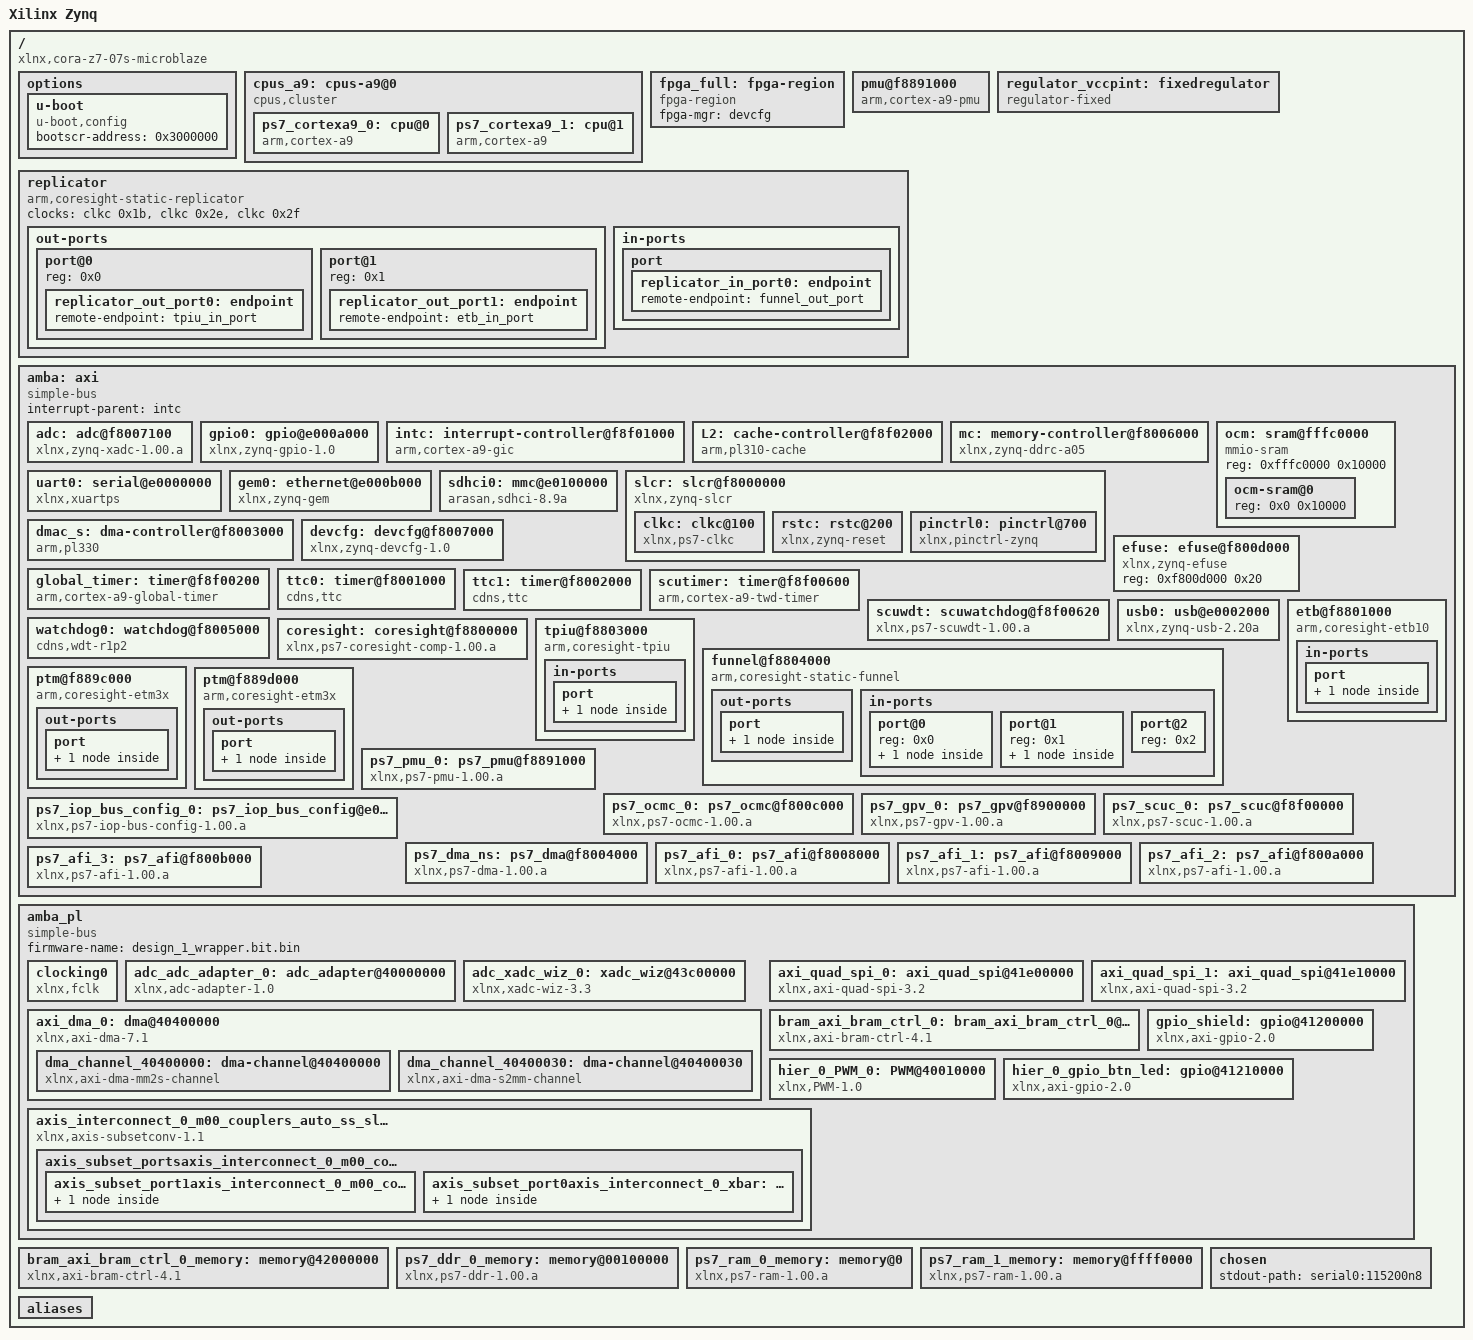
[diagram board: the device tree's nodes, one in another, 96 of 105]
/dts-v1/;
/ {
        #address-cells = <0x1>;
        #size-cells = <0x1>;
        compatible = "xlnx,cora-z7-07s-microblaze";
        model = "Xilinx Zynq";
        board = "cora-z7-07s";
        device_id = "7z007s";
        slrcount = <0x1>;
        family = "Zynq";
        speed_grade = "1";
        pruned-sdt = <0x1>;

        options {

                u-boot {
                        compatible = "u-boot,config";
                        bootscr-address = /bits/ 64 <0x3000000>;
                };
        };

        cpus_a9: cpus-a9@0 {
                phandle = <0x39>;
                #address-cells = <0x1>;
                #size-cells = <0x0>;
                compatible = "cpus,cluster";
                address-map = <0xf0000000 &amba 0xf0000000 0x10000000>,
                 <0x42000000 &bram_axi_bram_ctrl_0_memory 0x42000000 0x2000>,
                 <0x42000000 &bram_axi_bram_ctrl_0 0x42000000 0x2000>,
                 <0x100000 &ps7_ddr_0_memory 0x100000 0x1ff00000>,
                 <0x0 &ps7_ram_0_memory 0x0 0x30000>,
                 <0xffff0000 &ps7_ram_1_memory 0xffff0000 0xfe00>,
                 <0x40000000 &adc_adc_adapter_0 0x40000000 0x10000>,
                 <0x40010000 &hier_0_PWM_0 0x40010000 0x10000>,
                 <0x40400000 &axi_dma_0 0x40400000 0x10000>,
                 <0x41200000 &gpio_shield 0x41200000 0x10000>,
                 <0x41210000 &hier_0_gpio_btn_led 0x41210000 0x10000>,
                 <0x41e00000 &axi_quad_spi_0 0x41e00000 0x10000>,
                 <0x41e10000 &axi_quad_spi_1 0x41e10000 0x10000>,
                 <0x43c00000 &adc_xadc_wiz_0 0x43c00000 0x10000>,
                 <0xf8008000 &ps7_afi_0 0xf8008000 0x1000>,
                 <0xf8009000 &ps7_afi_1 0xf8009000 0x1000>,
                 <0xf800a000 &ps7_afi_2 0xf800a000 0x1000>,
                 <0xf800b000 &ps7_afi_3 0xf800b000 0x1000>,
                 <0xf8800000 &coresight 0xf8800000 0x100000>,
                 <0xf8006000 &mc 0xf8006000 0x1000>,
                 <0xf8007000 &devcfg 0xf8007000 0x100>,
                 <0xf8004000 &ps7_dma_ns 0xf8004000 0x1000>,
                 <0xf8003000 &dmac_s 0xf8003000 0x1000>,
                 <0xe000b000 &gem0 0xe000b000 0x1000>,
                 <0xf8f00200 &global_timer 0xf8f00200 0x100>,
                 <0xe000a000 &gpio0 0xe000a000 0x1000>,
                 <0xf8900000 &ps7_gpv_0 0xf8900000 0x100000>,
                 <0xf8f01000 &intc 0xf8f01000 0x1000>,
                 <0xe0200000 &ps7_iop_bus_config_0 0xe0200000 0x1000>,
                 <0xf8f02000 &L2 0xf8f02000 0x1000>,
                 <0xf800c000 &ps7_ocmc_0 0xf800c000 0x1000>,
                 <0xf8891000 &ps7_pmu_0 0xf8891000 0x1000>,
                 <0xf8f00000 &ps7_scuc_0 0xf8f00000 0xfd>,
                 <0xf8f00600 &scutimer 0xf8f00600 0x20>,
                 <0xf8f00620 &scuwdt 0xf8f00620 0xe0>,
                 <0xe0100000 &sdhci0 0xe0100000 0x1000>,
                 <0xf8000000 &slcr 0xf8000000 0x1000>,
                 <0xf8001000 &ttc0 0xf8001000 0x1000>,
                 <0xe0000000 &uart0 0xe0000000 0x1000>,
                 <0xe0002000 &usb0 0xe0002000 0x1000>,
                 <0xf8007100 &adc 0xf8007100 0x21>;
                #ranges-address-cells = <0x1>;
                #ranges-size-cells = <0x1>;

                ps7_cortexa9_0: cpu@0 {
                        phandle = <0x34>;
                        compatible = "arm,cortex-a9";
                        device_type = "cpu";
                        reg = <0x0>;
                        clocks = <&clkc 0x3>;
                        clock-latency = <0x3e8>;
                        cpu0-supply = <&regulator_vccpint>;
                        operating-points = <0xa2c2b 0xf4240 0x51616 0xf4240>;
                        xlnx,i-cache-size = <0x8000>;
                        xlnx,d-cache-line-size = <0x14>;
                        xlnx,i-cache-line-size = <0x14>;
                        xlnx,cpu-1x-clk-freq-hz = <0x6750918>;
                        xlnx,ip-name = "ps7_cortexa9";
                        xlnx,d-cache-size = <0x8000>;
                        xlnx,num-cores = <0x1>;
                        xlnx,cpu-clk-freq-hz = <0x26be3680>;
                        bus-handle = <0x1>;
                };

                ps7_cortexa9_1: cpu@1 {
                        phandle = <0x36>;
                        compatible = "arm,cortex-a9";
                        device_type = "cpu";
                        reg = <0x1>;
                        clocks = <&clkc 0x3>;
                };
        };

        fpga_full: fpga-region {
                phandle = <0x3a>;
                compatible = "fpga-region";
                fpga-mgr = <&devcfg>;
                #address-cells = <0x1>;
                #size-cells = <0x1>;
                ranges;
        };

        pmu@f8891000 {
                compatible = "arm,cortex-a9-pmu";
                interrupts = <0x0 0x5 0x4 0x0 0x6 0x4>;
                interrupt-parent = <&intc>;
                reg = <0xf8891000 0x1000 0xf8893000 0x1000>;
        };

        regulator_vccpint: fixedregulator {
                phandle = <0x2b>;
                compatible = "regulator-fixed";
                regulator-name = "VCCPINT";
                regulator-min-microvolt = <0xf4240>;
                regulator-max-microvolt = <0xf4240>;
                regulator-boot-on;
                regulator-always-on;
        };

        replicator {
                compatible = "arm,coresight-static-replicator";
                clocks = <&clkc 0x1b>,
                 <&clkc 0x2e>,
                 <&clkc 0x2f>;
                clock-names = "apb_pclk", "dbg_trc", "dbg_apb";

                out-ports {
                        #address-cells = <0x1>;
                        #size-cells = <0x0>;

                        port@0 {
                                reg = <0x0>;

                                replicator_out_port0: endpoint {
                                        phandle = <0x30>;
                                        remote-endpoint = <&tpiu_in_port>;
                                };
                        };

                        port@1 {
                                reg = <0x1>;

                                replicator_out_port1: endpoint {
                                        phandle = <0x2f>;
                                        remote-endpoint = <&etb_in_port>;
                                };
                        };
                };

                in-ports {

                        port {

                                replicator_in_port0: endpoint {
                                        phandle = <0x31>;
                                        remote-endpoint = <&funnel_out_port>;
                                };
                        };
                };
        };

        amba: axi {
                phandle = <0x1>;
                bootph-all;
                compatible = "simple-bus";
                #address-cells = <0x1>;
                #size-cells = <0x1>;
                interrupt-parent = <&intc>;
                ranges;

                adc: adc@f8007100 {
                        phandle = <0x29>;
                        compatible = "xlnx,zynq-xadc-1.00.a";
                        reg = <0xf8007100 0x20>;
                        interrupts = <0x0 0x7 0x4>;
                        interrupt-parent = <&intc>;
                        clocks = <&clkc 0xc>;
                        status = "okay";
                        xlnx,ip-name = "ps7_xadc";
                        xlnx,name = "ps7_xadc_0";
                };

                gpio0: gpio@e000a000 {
                        phandle = <0x1a>;
                        compatible = "xlnx,zynq-gpio-1.0";
                        #gpio-cells = <0x2>;
                        clocks = <&clkc 0x2a>;
                        gpio-controller;
                        interrupt-controller;
                        #interrupt-cells = <0x2>;
                        interrupt-parent = <&intc>;
                        interrupts = <0x0 0x14 0x4>;
                        reg = <0xe000a000 0x1000>;
                        xlnx,mio-gpio-mask = <0x5600>;
                        status = "okay";
                        gpio-mask-high = <0x0>;
                        xlnx,emio-gpio-width = <0x40>;
                        xlnx,ip-name = "ps7_gpio";
                        gpio-mask-low = <0x5600>;
                        emio-gpio-width = <0x40>;
                        xlnx,name = "ps7_gpio_0";
                };

                intc: interrupt-controller@f8f01000 {
                        phandle = <0x1c>;
                        compatible = "arm,cortex-a9-gic";
                        #interrupt-cells = <0x3>;
                        interrupt-controller;
                        reg = <0xf8f01000 0x1000 0xf8f00100 0x100>;
                        status = "okay";
                        xlnx,irq-f2p-mode = "DIRECT";
                        xlnx,ip-name = "ps7_intc_dist";
                        xlnx,name = "ps7_intc_dist_0";
                };

                L2: cache-controller@f8f02000 {
                        phandle = <0x1e>;
                        compatible = "arm,pl310-cache";
                        reg = <0xf8f02000 0x1000>;
                        interrupts = <0x0 0x2 0x4>;
                        arm,data-latency = <0x3 0x2 0x2>;
                        arm,tag-latency = <0x2 0x2 0x2>;
                        cache-unified;
                        cache-level = <0x2>;
                        status = "okay";
                        xlnx,ip-name = "ps7_pl310";
                        xlnx,name = "ps7_pl310_0";
                };

                mc: memory-controller@f8006000 {
                        phandle = <0x14>;
                        compatible = "xlnx,zynq-ddrc-a05";
                        reg = <0xf8006000 0x1000>;
                        status = "okay";
                        xlnx,ddr-clk-freq-hz = <0x1f4add40>;
                        xlnx,ip-name = "ps7_ddrc";
                        xlnx,has-ecc = <0x0>;
                        xlnx,name = "ps7_ddrc_0";
                };

                ocm: sram@fffc0000 {
                        phandle = <0x3f>;
                        compatible = "mmio-sram";
                        reg = <0xfffc0000 0x10000>;
                        #address-cells = <0x1>;
                        #size-cells = <0x1>;
                        ranges = <0x0 0xfffc0000 0x10000>;

                        ocm-sram@0 {
                                reg = <0x0 0x10000>;
                        };
                };

                uart0: serial@e0000000 {
                        phandle = <0x27>;
                        compatible = "xlnx,xuartps", "cdns,uart-r1p8";
                        status = "okay";
                        clocks = <&clkc 0x17>,
                         <&clkc 0x28>;
                        clock-names = "uart_clk", "pclk";
                        reg = <0xe0000000 0x1000>;
                        interrupts = <0x0 0x1b 0x4>;
                        interrupt-parent = <&intc>;
                        device_type = "serial";
                        xlnx,clock-freq = <0x5f5e100>;
                        xlnx,has-modem = <0x0>;
                        xlnx,ip-name = "ps7_uart";
                        cts-override;
                        port-number = <0x0>;
                        xlnx,uart-clk-freq-hz = <0x5f5e100>;
                        xlnx,name = "ps7_uart_0";
                };

                gem0: ethernet@e000b000 {
                        phandle = <0x18>;
                        compatible = "xlnx,zynq-gem", "cdns,gem";
                        reg = <0xe000b000 0x1000>;
                        status = "okay";
                        interrupts = <0x0 0x16 0x4>;
                        interrupt-parent = <&intc>;
                        clocks = <&clkc 0x1e>,
                         <&clkc 0x1e>,
                         <&clkc 0xd>;
                        clock-names = "pclk", "hclk", "tx_clk";
                        #address-cells = <0x1>;
                        #size-cells = <0x0>;
                        xlnx,has-mdio = <0x1>;
                        phy-mode = "rgmii-id";
                        xlnx,enet-slcr-1000mbps-div0 = <0x8>;
                        xlnx,enet-slcr-10mbps-div0 = <0x8>;
                        enet-reset = <0x1a 0x9 0x0>;
                        xlnx,enet-slcr-1000mbps-div1 = <0x1>;
                        xlnx,enet-slcr-10mbps-div1 = <0x32>;
                        xlnx,ip-name = "ps7_ethernet";
                        xlnx,eth-mode = <0x1>;
                        xlnx,enet-reset = "MIO , 9";
                        xlnx,enet-clk-freq-hz = <0x7735940>;
                        xlnx,enet-slcr-100mbps-div0 = <0x8>;
                        xlnx,ptp-enet-clock = <0x6750918>;
                        xlnx,enet-slcr-100mbps-div1 = <0x5>;
                        xlnx,name = "ps7_ethernet_0";
                };

                sdhci0: mmc@e0100000 {
                        phandle = <0x24>;
                        compatible = "arasan,sdhci-8.9a";
                        status = "okay";
                        clock-names = "clk_xin", "clk_ahb";
                        clocks = <&clkc 0x15>,
                         <&clkc 0x20>;
                        interrupt-parent = <&intc>;
                        interrupts = <0x0 0x18 0x4>;
                        reg = <0xe0100000 0x1000>;
                        xlnx,has-power = <0x0>;
                        xlnx,ip-name = "ps7_sdio";
                        xlnx,sdio-clk-freq-hz = <0x5f5e100>;
                        xlnx,has-wp = <0x0>;
                        xlnx,has-cd = <0x1>;
                        xlnx,name = "ps7_sd_0";
                };

                slcr: slcr@f8000000 {
                        phandle = <0x25>;
                        bootph-all;
                        #address-cells = <0x1>;
                        #size-cells = <0x1>;
                        compatible = "xlnx,zynq-slcr", "syscon", "simple-mfd";
                        reg = <0xf8000000 0x1000>;
                        ranges;
                        status = "okay";
                        xlnx,ip-name = "ps7_slcr";
                        xlnx,name = "ps7_slcr_0";

                        clkc: clkc@100 {
                                phandle = <0x2a>;
                                bootph-all;
                                #clock-cells = <0x1>;
                                compatible = "xlnx,ps7-clkc";
                                fclk-enable = <0x1>;
                                clock-output-names = "armpll", "ddrpll", "iopll", "cpu_6or4x", "cpu_3or2x", "cpu_2x", "cpu_1x", "ddr2x", "ddr3x", "dci", "lqspi", "smc", "pcap", "gem0", "gem1", "fclk0", "fclk1", "fclk2", "fclk3", "can0", "can1", "sdio0", "sdio1", "uart0", "uart1", "spi0", "spi1", "dma", "usb0_aper", "usb1_aper", "gem0_aper", "gem1_aper", "sdio0_aper", "sdio1_aper", "spi0_aper", "spi1_aper", "can0_aper", "can1_aper", "i2c0_aper", "i2c1_aper", "uart0_aper", "uart1_aper", "gpio_aper", "lqspi_aper", "smc_aper", "swdt", "dbg_trc", "dbg_apb";
                                reg = <0x100 0x100>;
                                ps-clk-frequency = <0x2faf080>;
                        };

                        rstc: rstc@200 {
                                phandle = <0x49>;
                                compatible = "xlnx,zynq-reset";
                                reg = <0x200 0x48>;
                                #reset-cells = <0x1>;
                                syscon = <&slcr>;
                        };

                        pinctrl0: pinctrl@700 {
                                phandle = <0x4a>;
                                compatible = "xlnx,pinctrl-zynq";
                                reg = <0x700 0x200>;
                                syscon = <&slcr>;
                        };
                };

                dmac_s: dma-controller@f8003000 {
                        phandle = <0x17>;
                        compatible = "arm,pl330", "arm,primecell";
                        reg = <0xf8003000 0x1000>;
                        interrupt-parent = <&intc>;
                        interrupts = <0x0 0xd 0x4 0x0 0xe 0x4 0x0 0xf 0x4 0x0 0x10 0x4 0x0 0x11 0x4 0x0 0x28 0x4 0x0 0x29 0x4 0x0 0x2a 0x4 0x0 0x2b 0x4>;
                        #dma-cells = <0x1>;
                        clocks = <&clkc 0x1b>;
                        clock-names = "apb_pclk";
                        status = "okay";
                        xlnx,ip-name = "ps7_dma";
                        xlnx,is-secure;
                        xlnx,name = "ps7_dma_s";
                };

                devcfg: devcfg@f8007000 {
                        phandle = <0x15>;
                        compatible = "xlnx,zynq-devcfg-1.0";
                        reg = <0xf8007000 0x100>;
                        interrupt-parent = <&intc>;
                        interrupts = <0x0 0x8 0x4>;
                        clocks = <&clkc 0xc>,
                         <&clkc 0xf>,
                         <&clkc 0x10>,
                         <&clkc 0x11>,
                         <&clkc 0x12>;
                        clock-names = "ref_clk", "fclk0", "fclk1", "fclk2", "fclk3";
                        syscon = <&slcr>;
                        status = "okay";
                        xlnx,ip-name = "ps7_dev_cfg";
                        xlnx,name = "ps7_dev_cfg_0";
                };

                efuse: efuse@f800d000 {
                        phandle = <0x4b>;
                        compatible = "xlnx,zynq-efuse";
                        reg = <0xf800d000 0x20>;
                };

                global_timer: timer@f8f00200 {
                        phandle = <0x19>;
                        compatible = "arm,cortex-a9-global-timer";
                        reg = <0xf8f00200 0x20>;
                        interrupts = <0x1 0xb 0x301>;
                        interrupt-parent = <&intc>;
                        clocks = <&clkc 0x4>;
                        status = "okay";
                        xlnx,ip-name = "ps7_globaltimer";
                        xlnx,name = "ps7_globaltimer_0";
                };

                ttc0: timer@f8001000 {
                        phandle = <0x26>;
                        interrupt-parent = <&intc>;
                        interrupts = <0x0 0xa 0x4 0x0 0xb 0x4 0x0 0xc 0x4>;
                        compatible = "cdns,ttc";
                        clocks = <&clkc 0x6>;
                        reg = <0xf8001000 0x1000>;
                        xlnx,ttc-clk2-freq-hz = <0x6750918>;
                        xlnx,ttc-clk1-clksrc = <0x0>;
                        status = "okay";
                        xlnx,clock-freq = <0x6750918>;
                        xlnx,ttc-clk2-clksrc = <0x0>;
                        xlnx,ip-name = "ps7_ttc";
                        xlnx,ttc-clk0-freq-hz = <0x6750918>;
                        xlnx,ttc-clk1-freq-hz = <0x6750918>;
                        xlnx,ttc-clk0-clksrc = <0x0>;
                        xlnx,name = "ps7_ttc_0";
                };

                ttc1: timer@f8002000 {
                        phandle = <0x4c>;
                        interrupt-parent = <&intc>;
                        interrupts = <0x0 0x25 0x4 0x0 0x26 0x4 0x0 0x27 0x4>;
                        compatible = "cdns,ttc";
                        clocks = <&clkc 0x6>;
                        reg = <0xf8002000 0x1000>;
                };

                scutimer: timer@f8f00600 {
                        phandle = <0x22>;
                        bootph-all;
                        interrupt-parent = <&intc>;
                        interrupts = <0x1 0xd 0x301>;
                        compatible = "arm,cortex-a9-twd-timer";
                        reg = <0xf8f00600 0x20>;
                        clocks = <&clkc 0x4>;
                        status = "okay";
                        xlnx,ip-name = "ps7_scutimer";
                        xlnx,name = "ps7_scutimer_0";
                };

                scuwdt: scuwatchdog@f8f00620 {
                        phandle = <0x23>;
                        interrupt-parent = <&intc>;
                        interrupts = <0x1 0xe 0x4>;
                        compatible = "xlnx,ps7-scuwdt-1.00.a";
                        reg = <0xf8f00620 0xe0>;
                        status = "okay";
                        xlnx,ip-name = "ps7_scuwdt";
                        xlnx,name = "ps7_scuwdt_0";
                };

                usb0: usb@e0002000 {
                        phandle = <0x28>;
                        compatible = "xlnx,zynq-usb-2.20a", "chipidea,usb2";
                        status = "okay";
                        clocks = <&clkc 0x1c>;
                        interrupt-parent = <&intc>;
                        interrupts = <0x0 0x15 0x4>;
                        reg = <0xe0002000 0x1000>;
                        phy_type = "ulpi";
                        xlnx,usb-reset = "MIO , 46";
                        xlnx,ip-name = "ps7_usb";
                        xlnx,enable-superspeed = <0x0>;
                        usb-reset = <0x1a 0x2e 0x0>;
                        xlnx,name = "ps7_usb_0";
                };

                watchdog0: watchdog@f8005000 {
                        phandle = <0x4e>;
                        clocks = <&clkc 0x2d>;
                        compatible = "cdns,wdt-r1p2";
                        interrupt-parent = <&intc>;
                        interrupts = <0x0 0x9 0x1>;
                        reg = <0xf8005000 0x1000>;
                        timeout-sec = <0xa>;
                };

                coresight: coresight@f8800000 {
                        phandle = <0x13>;
                        compatible = "xlnx,ps7-coresight-comp-1.00.a";
                        status = "okay";
                        reg = <0xf8800000 0x100000>;
                        xlnx,ip-name = "ps7_coresight_comp";
                        xlnx,name = "ps7_coresight_comp_0";
                };

                etb@f8801000 {
                        compatible = "arm,coresight-etb10", "arm,primecell";
                        reg = <0xf8801000 0x1000>;
                        clocks = <&clkc 0x1b>,
                         <&clkc 0x2e>,
                         <&clkc 0x2f>;
                        clock-names = "apb_pclk", "dbg_trc", "dbg_apb";

                        in-ports {

                                port {

                                        etb_in_port: endpoint {
                                                phandle = <0x2d>;
                                                remote-endpoint = <&replicator_out_port1>;
                                        };
                                };
                        };
                };

                tpiu@f8803000 {
                        compatible = "arm,coresight-tpiu", "arm,primecell";
                        reg = <0xf8803000 0x1000>;
                        clocks = <&clkc 0x1b>,
                         <&clkc 0x2e>,
                         <&clkc 0x2f>;
                        clock-names = "apb_pclk", "dbg_trc", "dbg_apb";

                        in-ports {

                                port {

                                        tpiu_in_port: endpoint {
                                                phandle = <0x2c>;
                                                remote-endpoint = <&replicator_out_port0>;
                                        };
                                };
                        };
                };

                funnel@f8804000 {
                        compatible = "arm,coresight-static-funnel", "arm,primecell";
                        reg = <0xf8804000 0x1000>;
                        clocks = <&clkc 0x1b>,
                         <&clkc 0x2e>,
                         <&clkc 0x2f>;
                        clock-names = "apb_pclk", "dbg_trc", "dbg_apb";

                        out-ports {

                                port {

                                        funnel_out_port: endpoint {
                                                phandle = <0x2e>;
                                                remote-endpoint = <&replicator_in_port0>;
                                        };
                                };
                        };

                        in-ports {
                                #address-cells = <0x1>;
                                #size-cells = <0x0>;

                                port@0 {
                                        reg = <0x0>;

                                        funnel0_in_port0: endpoint {
                                                phandle = <0x35>;
                                                remote-endpoint = <&ptm0_out_port>;
                                        };
                                };

                                port@1 {
                                        reg = <0x1>;

                                        funnel0_in_port1: endpoint {
                                                phandle = <0x37>;
                                                remote-endpoint = <&ptm1_out_port>;
                                        };
                                };

                                port@2 {
                                        reg = <0x2>;
                                };
                        };
                };

                ptm@f889c000 {
                        compatible = "arm,coresight-etm3x", "arm,primecell";
                        reg = <0xf889c000 0x1000>;
                        clocks = <&clkc 0x1b>,
                         <&clkc 0x2e>,
                         <&clkc 0x2f>;
                        clock-names = "apb_pclk", "dbg_trc", "dbg_apb";
                        cpu = <&ps7_cortexa9_0>;

                        out-ports {

                                port {

                                        ptm0_out_port: endpoint {
                                                phandle = <0x32>;
                                                remote-endpoint = <&funnel0_in_port0>;
                                        };
                                };
                        };
                };

                ptm@f889d000 {
                        compatible = "arm,coresight-etm3x", "arm,primecell";
                        reg = <0xf889d000 0x1000>;
                        clocks = <&clkc 0x1b>,
                         <&clkc 0x2e>,
                         <&clkc 0x2f>;
                        clock-names = "apb_pclk", "dbg_trc", "dbg_apb";
                        cpu = <&ps7_cortexa9_1>;

                        out-ports {

                                port {

                                        ptm1_out_port: endpoint {
                                                phandle = <0x33>;
                                                remote-endpoint = <&funnel0_in_port1>;
                                        };
                                };
                        };
                };

                ps7_pmu_0: ps7_pmu@f8891000 {
                        phandle = <0x20>;
                        compatible = "xlnx,ps7-pmu-1.00.a";
                        status = "okay";
                        xlnx,ip-name = "ps7_pmu";
                        reg = <0xf8891000 0x1000 0xf8893000 0x1000>;
                        xlnx,name = "ps7_pmu_0";
                };

                ps7_ocmc_0: ps7_ocmc@f800c000 {
                        phandle = <0x1f>;
                        compatible = "xlnx,ps7-ocmc-1.00.a";
                        status = "okay";
                        xlnx,ip-name = "ps7_ocmc";
                        reg = <0xf800c000 0x1000>;
                        xlnx,name = "ps7_ocmc_0";
                };

                ps7_gpv_0: ps7_gpv@f8900000 {
                        phandle = <0x1b>;
                        compatible = "xlnx,ps7-gpv-1.00.a";
                        status = "okay";
                        xlnx,ip-name = "ps7_gpv";
                        reg = <0xf8900000 0x100000>;
                        xlnx,name = "ps7_gpv_0";
                };

                ps7_scuc_0: ps7_scuc@f8f00000 {
                        phandle = <0x21>;
                        compatible = "xlnx,ps7-scuc-1.00.a";
                        status = "okay";
                        xlnx,ip-name = "ps7_scuc";
                        reg = <0xf8f00000 0xfd>;
                        xlnx,name = "ps7_scuc_0";
                };

                ps7_iop_bus_config_0: ps7_iop_bus_config@e0200000 {
                        phandle = <0x1d>;
                        compatible = "xlnx,ps7-iop-bus-config-1.00.a";
                        status = "okay";
                        xlnx,ip-name = "ps7_iop_bus_config";
                        reg = <0xe0200000 0x1000>;
                        xlnx,name = "ps7_iop_bus_config_0";
                };

                ps7_dma_ns: ps7_dma@f8004000 {
                        phandle = <0x16>;
                        compatible = "xlnx,ps7-dma-1.00.a";
                        status = "okay";
                        xlnx,ip-name = "ps7_dma";
                        xlnx,is-secure;
                        reg = <0xf8004000 0x1000>;
                        xlnx,name = "ps7_dma_ns";
                };

                ps7_afi_0: ps7_afi@f8008000 {
                        phandle = <0xf>;
                        compatible = "xlnx,ps7-afi-1.00.a";
                        status = "okay";
                        xlnx,ip-name = "ps7_afi";
                        reg = <0xf8008000 0x1000>;
                        xlnx,name = "ps7_afi_0";
                };

                ps7_afi_1: ps7_afi@f8009000 {
                        phandle = <0x10>;
                        compatible = "xlnx,ps7-afi-1.00.a";
                        status = "okay";
                        xlnx,ip-name = "ps7_afi";
                        reg = <0xf8009000 0x1000>;
                        xlnx,name = "ps7_afi_1";
                };

                ps7_afi_2: ps7_afi@f800a000 {
                        phandle = <0x11>;
                        compatible = "xlnx,ps7-afi-1.00.a";
                        status = "okay";
                        xlnx,ip-name = "ps7_afi";
                        reg = <0xf800a000 0x1000>;
                        xlnx,name = "ps7_afi_2";
                };

                ps7_afi_3: ps7_afi@f800b000 {
                        phandle = <0x12>;
                        compatible = "xlnx,ps7-afi-1.00.a";
                        status = "okay";
                        xlnx,ip-name = "ps7_afi";
                        reg = <0xf800b000 0x1000>;
                        xlnx,name = "ps7_afi_3";
                };
        };

        amba_pl: amba_pl {
                phandle = <0x54>;
                ranges;
                compatible = "simple-bus";
                #address-cells = <0x1>;
                #size-cells = <0x1>;
                firmware-name = "design_1_wrapper.bit.bin";

                clocking0: clocking0 {
                        phandle = <0x55>;
                        compatible = "xlnx,fclk";
                        assigned-clocks = <&clkc 0xf>;
                        assigned-clock-rates = <0x2faf080>;
                        #clock-cells = <0x0>;
                        clock-output-names = "fabric_clk";
                        clocks = <&clkc 0xf>;
                };

                adc_adc_adapter_0: adc_adapter@40000000 {
                        phandle = <0x7>;
                        interrupts = <0x0 0x20 0x4>;
                        compatible = "xlnx,adc-adapter-1.0";
                        xlnx,ii = "undef";
                        xlnx,machine = <0x40>;
                        xlnx,s-axi-control-addr-width = <0x5>;
                        interrupt-parent = <&intc>;
                        xlnx,ip-name = "adc_adapter";
                        reg = <0x40000000 0x10000>;
                        clocks = <&clkc 0xf>;
                        xlnx,clk-period = <0xa>;
                        xlnx,s-axi-control-data-width = <0x20>;
                        xlnx,edk-iptype = "PERIPHERAL";
                        status = "okay";
                        clock-names = "ap_clk";
                        interrupt-names = "interrupt";
                        xlnx,combinational = <0x0>;
                        xlnx,latency = "undef";
                        xlnx,name = "adc_adc_adapter_0";
                };

                adc_xadc_wiz_0: xadc_wiz@43c00000 {
                        phandle = <0xe>;
                        xlnx,vccpint-alarm-upper = <0x1>;
                        xlnx,vccint-alarm-upper = <0xfb770>;
                        xlnx,timing-mode = "Continuous";
                        xlnx,enable-dclk;
                        xlnx,has-vccpint-alarm = <0x0>;
                        xlnx,alarm-limit-r2 = <0xa147>;
                        xlnx,has-jtagbusy = <0x0>;
                        xlnx,vbram-alarm-upper = <0x100590>;
                        xlnx,enable-jtagmodified;
                        xlnx,has-vbram-alarm = <0x0>;
                        xlnx,alarm-limit-r3 = <0xca33>;
                        xlnx,has-axi = <0x1>;
                        xlnx,vaux0 = <0x0>;
                        xlnx,alarm-limit-r4 = <0xa93a>;
                        xlnx,has-busy = <0x1>;
                        xlnx,enable-channel;
                        xlnx,vaux1 = <0x0>;
                        xlnx,has-vccaux-alarm = <0x0>;
                        xlnx,alarm-limit-r5 = <0x52c6>;
                        xlnx,dclk-frequency = <0x32>;
                        xlnx,vaux2 = <0x0>;
                        xlnx,alarm-limit-r6 = <0x9555>;
                        xlnx,vaux3 = <0x0>;
                        xlnx,ip-name = "xadc_wiz";
                        xlnx,alarm-limit-r7 = <0xae4e>;
                        xlnx,configuration-r0 = <0x3>;
                        xlnx,has-drp = <0x0>;
                        xlnx,vaux4 = <0x0>;
                        xlnx,sim-file-rel-path = "./";
                        reg = <0x43c00000 0x10000>;
                        xlnx,alarm-limit-r8 = <0x5999>;
                        xlnx,configuration-r1 = <0x31af>;
                        xlnx,external-mux-channel = "VP_VN";
                        xlnx,temperature-alarm-trigger = <0x55>;
                        xlnx,vaux5 = <0x0>;
                        xlnx,alarm-limit-r9 = <0x5111>;
                        xlnx,configuration-r2 = <0x200>;
                        xlnx,has-jtaglocked = <0x0>;
                        xlnx,vaux6 = <0x0>;
                        xlnx,vaux7 = <0x0>;
                        xlnx,vaux8 = <0x0>;
                        xlnx,vaux9 = <0x0>;
                        xlnx,vaux10 = <0x0>;
                        xlnx,has-vn = <0x1>;
                        xlnx,has-vccpaux-alarm = <0x0>;
                        xlnx,acquisition-time = <0x4>;
                        xlnx,vaux11 = <0x0>;
                        xlnx,has-temp-bus = <0x0>;
                        xlnx,xadc-starup-selection = "single_channel";
                        xlnx,enable-busy;
                        xlnx,data-width = <0x20>;
                        xlnx,vaux12 = <0x0>;
                        xlnx,sim-file-sel = "Default";
                        xlnx,has-vp = <0x1>;
                        xlnx,ip-type = <0x0>;
                        xlnx,temperature-alarm-ot-reset = <0x46>;
                        xlnx,vaux13 = <0x0>;
                        xlnx,enable-convst;
                        xlnx,vaux14 = <0x0>;
                        xlnx,vccpaux-alarm-lower = <0x1a17b0>;
                        xlnx,vccaux-alarm-lower = <0x1ab3f0>;
                        xlnx,vaux15 = <0x0>;
                        compatible = "xlnx,xadc-wiz-3.3", "xlnx,axi-xadc-1.00.a";
                        xlnx,has-external-mux = <0x0>;
                        xlnx,sampling-rate = <0xdf 0xe0288f62>;
                        xlnx,has-reset = <0x0>;
                        xlnx,adc-conversion-rate = <0x3c2>;
                        xlnx,vccddro-alarm-lower = <0x124f80>;
                        xlnx,enable-calibration-averaging;
                        xlnx,has-user-temp-alarm = <0x0>;
                        xlnx,enable-axi4stream;
                        xlnx,has-ot-alarm = <0x0>;
                        xlnx,has-convst = <0x0>;
                        xlnx,single-channel-selection = "VP_VN";
                        xlnx,startup-channel-selection = "single_channel";
                        xlnx,interface-selection = "Enable_AXI";
                        xlnx,vccpaux-alarm-upper = <0x1b7740>;
                        xlnx,vccaux-alarm-upper = <0x1cd6d0>;
                        status = "okay";
                        xlnx,sensor-offset-and-gain-calibration;
                        xlnx,vccddro-alarm-upper = <0x1312d0>;
                        xlnx,name = "adc_xadc_wiz_0";
                        xlnx,external-mux = "none";
                        xlnx,enable-eoc;
                        xlnx,enable-jtaglocked;
                        xlnx,sim-file-name = "design";
                        xlnx,temperature-alarm-reset = <0x3c>;
                        xlnx,addr-width = <0x20>;
                        clocks = <&clkc 0xf>,
                         <&clkc 0xf>;
                        xlnx,alarm-limit-r10 = <0x5555>;
                        xlnx,alarm-limit-r11 = <0x5111>;
                        xlnx,alarm-limit-r12 = <0x9999>;
                        xlnx,edk-iptype = "PERIPHERAL";
                        xlnx,alarm-limit-r13 = <0x91eb>;
                        xlnx,sequencer-mode;
                        xlnx,enable-jtagbusy;
                        xlnx,alarm-limit-r14 = <0x6aaa>;
                        xlnx,include-intr = <0x1>;
                        xlnx,alarm-limit-r15 = <0x6666>;
                        xlnx,fifo-depth = <0x7>;
                        clock-names = "s_axi_aclk", "s_axis_aclk";
                        xlnx,has-eoc = <0x1>;
                        xlnx,temperature-alarm-ot-trigger = <0x7d>;
                        xlnx,has-channel = <0x1>;
                        xlnx,enable-eos;
                        xlnx,vccpint-alarm-lower = <0xe7ef0>;
                        xlnx,vccint-alarm-lower = <0xecd10>;
                        xlnx,has-dclk = <0x1>;
                        xlnx,vbram-alarm-lower = <0xe7ef0>;
                        xlnx,num-wave = <0x1>;
                        xlnx,sequence-r0 = <0x100>;
                        xlnx,has-jtagmodified = <0x0>;
                        xlnx,sequence-r1 = <0x0>;
                        xlnx,enable-drp;
                        xlnx,sequence-r2 = <0x0>;
                        xlnx,has-vccint-alarm = <0x0>;
                        xlnx,channel-averaging = "None";
                        xlnx,sequence-r3 = <0x0>;
                        xlnx,has-axi4stream = <0x1>;
                        xlnx,sequence-r4 = <0x0>;
                        xlnx,sequence-r5 = <0x0>;
                        xlnx,adc-offset-and-gain-calibration;
                        xlnx,waveform-type = "CONSTANT";
                        xlnx,sequence-r6 = <0x0>;
                        xlnx,vccddro-volt = "1_2";
                        xlnx,sequence-r7 = <0x0>;
                        xlnx,has-vccddro-alarm = <0x0>;
                        xlnx,alarm-limit-r0 = <0xb5ed>;
                        xlnx,has-convstclk = <0x0>;
                        xlnx,has-eos = <0x1>;
                        xlnx,stimulus-freq = <0x1>;
                        xlnx,single-channel-enable-calibration;
                        xlnx,alarm-limit-r1 = <0x57e4>;
                        xlnx,component-name = "design_1_xadc_wiz_0_0";
                        xlnx,external-muxaddr-enable = <0x0>;
                };

                axi_dma_0: dma@40400000 {
                        phandle = <0x9>;
                        interrupts = <0x0 0x1e 0x4 0x0 0x1f 0x4>;
                        compatible = "xlnx,axi-dma-7.1", "xlnx,axi-dma-1.00.a";
                        xlnx,s2mm-data-width = <0x20>;
                        xlnx,mm2s-burst-size = <0x10>;
                        xlnx,m-axi-mm2s-data-width = <0x20>;
                        xlnx,num-s2mm-channels = <0x1>;
                        xlnx,dlytmr-resolution = <0x7d>;
                        interrupt-parent = <&intc>;
                        xlnx,sg-length-width = <0xe>;
                        xlnx,prmry-is-aclk-async = <0x0>;
                        xlnx,include-s2mm-sf = <0x1>;
                        #dma-cells = <0x1>;
                        xlnx,ip-name = "axi_dma";
                        xlnx,single-interface = <0x0>;
                        xlnx,sg-include-stscntrl-strm = <0x0>;
                        xlnx,include-s2mm-dre = <0x0>;
                        reg = <0x40400000 0x10000>;
                        xlnx,addr-width = <0x20>;
                        xlnx,include-s2mm = <0x1>;
                        clocks = <&clkc 0xf>,
                         <&clkc 0xf>,
                         <&clkc 0xf>;
                        xlnx,s-axis-s2mm-tdata-width = <0x20>;
                        xlnx,micro-dma = <0x0>;
                        xlnx,increase-throughput = <0x0>;
                        xlnx,mm2s-data-width = <0x20>;
                        xlnx,addrwidth = <0x20>;
                        xlnx,sg-use-stsapp-length = <0x0>;
                        xlnx,m-axis-mm2s-tdata-width = <0x20>;
                        xlnx,edk-iptype = "PERIPHERAL";
                        xlnx,s2mm-burst-size = <0x10>;
                        xlnx,m-axi-s2mm-data-width = <0x20>;
                        xlnx,num-mm2s-channels = <0x1>;
                        xlnx,enable-multi-channel = <0x0>;
                        status = "okay";
                        xlnx,include-mm2s-sf = <0x1>;
                        clock-names = "m_axi_mm2s_aclk", "m_axi_s2mm_aclk", "s_axi_lite_aclk";
                        interrupt-names = "mm2s_introut", "s2mm_introut";
                        xlnx,include-mm2s = <0x1>;
                        xlnx,include-mm2s-dre = <0x0>;
                        xlnx,name = "axi_dma_0";

                        dma_channel_40400000: dma-channel@40400000 {
                                phandle = <0x56>;
                                interrupts = <0x0 0x1e 0x4>;
                                xlnx,datawidth = <0x20>;
                                xlnx,device-id = <0x0>;
                                compatible = "xlnx,axi-dma-mm2s-channel";
                                dma-channels = <0x1>;
                        };

                        dma_channel_40400030: dma-channel@40400030 {
                                phandle = <0x57>;
                                interrupts = <0x0 0x1f 0x4>;
                                xlnx,datawidth = <0x20>;
                                xlnx,device-id = <0x0>;
                                compatible = "xlnx,axi-dma-s2mm-channel";
                                dma-channels = <0x1>;
                        };
                };

                axi_quad_spi_0: axi_quad_spi@41e00000 {
                        phandle = <0xc>;
                        xlnx,select-xpm = <0x0>;
                        compatible = "xlnx,axi-quad-spi-3.2", "xlnx,xps-spi-2.00.a";
                        xlnx,lsb-stup = <0x0>;
                        xlnx,num-ss-bits = <0x1>;
                        xlnx,hasfifos = <0x1>;
                        xlnx,xip-mode = <0x0>;
                        xlnx,use-startup-ext = <0x0>;
                        xlnx,s-axi4-addr-width = <0x18>;
                        xlnx,byte-level-interrupt-en = <0x0>;
                        num-cs = <0x1>;
                        xlnx,xip-perf-mode = <0x1>;
                        xlnx,sck-ratio = <0x10>;
                        xlnx,s-axi4-id-width = <0x4>;
                        fifo-size = <0x10>;
                        xlnx,multiples16 = <0x1>;
                        xlnx,master-mode = <0x1>;
                        xlnx,shared-startup = <0x0>;
                        xlnx,ip-name = "axi_quad_spi";
                        xlnx,qspi-board-interface = "Custom";
                        reg = <0x41e00000 0x10000>;
                        xlnx,dual-quad-mode = <0x0>;
                        xlnx,new-seq-en = <0x1>;
                        bits-per-word = <0x8>;
                        clocks = <&clkc 0xf>,
                         <&clkc 0xf>;
                        xlnx,num-transfer-bits = <0x8>;
                        xlnx,spi-memory = <0x1>;
                        xlnx,s-axi4-data-width = <0x20>;
                        xlnx,edk-iptype = "PERIPHERAL";
                        xlnx,slaveonly = <0x0>;
                        xlnx,use-startup-int = <0x0>;
                        xlnx,use-startup = <0x0>;
                        xlnx,type-of-axi4-interface = <0x0>;
                        xlnx,async-clk = <0x0>;
                        xlnx,spi-mode = <0x0>;
                        xlnx,sck-ratio1 = <0x1>;
                        status = "okay";
                        xlnx,fifo-depth = <0x10>;
                        clock-names = "ext_spi_clk", "s_axi_aclk";
                        xlnx,use-board-flow;
                        xlnx,uc-family = <0x0>;
                        xlnx,spi-mem-addr-bits = <0x18>;
                        xlnx,axi-interface = <0x0>;
                        xlnx,Axi4-address = <0x0>;
                        xlnx,fifo-included = <0x1>;
                        xlnx,sub-family = "zynq";
                        xlnx,name = "axi_quad_spi_0";
                };

                axi_quad_spi_1: axi_quad_spi@41e10000 {
                        phandle = <0xd>;
                        xlnx,select-xpm = <0x0>;
                        compatible = "xlnx,axi-quad-spi-3.2", "xlnx,xps-spi-2.00.a";
                        xlnx,lsb-stup = <0x0>;
                        xlnx,num-ss-bits = <0x1>;
                        xlnx,hasfifos = <0x1>;
                        xlnx,xip-mode = <0x0>;
                        xlnx,use-startup-ext = <0x0>;
                        xlnx,s-axi4-addr-width = <0x18>;
                        xlnx,byte-level-interrupt-en = <0x0>;
                        num-cs = <0x1>;
                        xlnx,xip-perf-mode = <0x1>;
                        xlnx,sck-ratio = <0x10>;
                        xlnx,s-axi4-id-width = <0x4>;
                        fifo-size = <0x10>;
                        xlnx,multiples16 = <0x1>;
                        xlnx,master-mode = <0x1>;
                        xlnx,shared-startup = <0x0>;
                        xlnx,ip-name = "axi_quad_spi";
                        xlnx,qspi-board-interface = "Custom";
                        reg = <0x41e10000 0x10000>;
                        xlnx,dual-quad-mode = <0x0>;
                        xlnx,new-seq-en = <0x1>;
                        bits-per-word = <0x8>;
                        clocks = <&clkc 0xf>,
                         <&clkc 0xf>;
                        xlnx,num-transfer-bits = <0x8>;
                        xlnx,spi-memory = <0x1>;
                        xlnx,s-axi4-data-width = <0x20>;
                        xlnx,edk-iptype = "PERIPHERAL";
                        xlnx,slaveonly = <0x0>;
                        xlnx,use-startup-int = <0x0>;
                        xlnx,use-startup = <0x0>;
                        xlnx,type-of-axi4-interface = <0x0>;
                        xlnx,async-clk = <0x0>;
                        xlnx,spi-mode = <0x0>;
                        xlnx,sck-ratio1 = <0x1>;
                        status = "okay";
                        xlnx,fifo-depth = <0x10>;
                        clock-names = "ext_spi_clk", "s_axi_aclk";
                        xlnx,use-board-flow;
                        xlnx,uc-family = <0x0>;
                        xlnx,spi-mem-addr-bits = <0x18>;
                        xlnx,axi-interface = <0x0>;
                        xlnx,Axi4-address = <0x0>;
                        xlnx,fifo-included = <0x1>;
                        xlnx,sub-family = "zynq";
                        xlnx,name = "axi_quad_spi_1";
                };

                bram_axi_bram_ctrl_0: bram_axi_bram_ctrl_0@42000000 {
                        phandle = <0x3>;
                        xlnx,protocol = "AXI4";
                        xlnx,edk-special = "BRAM_CTRL";
                        compatible = "xlnx,axi-bram-ctrl-4.1", "xlnx,axi-bram-ctrl";
                        xlnx,ecc-onoff-reset-value = <0x0>;
                        xlnx,ecc-type = <0x0>;
                        xlnx,rd-cmd-optimization = <0x0>;
                        xlnx,memory-depth = <0x800>;
                        xlnx,use-ecc = <0x0>;
                        xlnx,fault-inject = <0x0>;
                        xlnx,ip-name = "axi_bram_ctrl";
                        reg = <0x42000000 0x2000>;
                        xlnx,bmg-instance = "EXTERNAL";
                        clocks = <&clkc 0xf>;
                        xlnx,s-axi-ctrl-addr-width = <0x20>;
                        xlnx,read-latency = <0x1>;
                        xlnx,id-width = <0x0>;
                        xlnx,s-axi-supports-narrow-burst = <0x0>;
                        xlnx,supports-narrow-burst = <0x0>;
                        xlnx,single-port-bram = <0x0>;
                        xlnx,ecc = <0x0>;
                        xlnx,edk-iptype = "PERIPHERAL";
                        status = "okay";
                        clock-names = "s_axi_aclk";
                        xlnx,data-width = <0x20>;
                        xlnx,bram-addr-width = <0xb>;
                        xlnx,bram-inst-mode = "EXTERNAL";
                        xlnx,s-axi-ctrl-data-width = <0x20>;
                        xlnx,mem-depth = <0x800>;
                        xlnx,s-axi-id-width = <0x1>;
                        xlnx,name = "bram_axi_bram_ctrl_0";
                };

                gpio_shield: gpio@41200000 {
                        phandle = <0xa>;
                        #interrupt-cells = <0x2>;
                        interrupts = <0x0 0x21 0x4>;
                        xlnx,gpio-board-interface = "shield_dp0_dp13";
                        compatible = "xlnx,axi-gpio-2.0", "xlnx,xps-gpio-1.00.a";
                        xlnx,all-outputs = <0x0>;
                        #gpio-cells = <0x2>;
                        xlnx,gpio-width = <0xe>;
                        interrupt-parent = <&intc>;
                        xlnx,dout-default = <0x0>;
                        xlnx,is-dual = <0x1>;
                        xlnx,ip-name = "axi_gpio";
                        xlnx,tri-default-2 = <0xffffffff>;
                        reg = <0x41200000 0x10000>;
                        xlnx,all-inputs-2 = <0x0>;
                        clocks = <&clkc 0xf>;
                        xlnx,all-outputs-2 = <0x1>;
                        gpio-controller;
                        device_type = "gpio";
                        xlnx,interrupt-present = <0x1>;
                        xlnx,gpio2-board-interface = "Custom";
                        xlnx,edk-iptype = "PERIPHERAL";
                        xlnx,dout-default-2 = <0x0>;
                        status = "okay";
                        xlnx,gpio2-width = <0x4>;
                        clock-names = "s_axi_aclk";
                        xlnx,use-board-flow;
                        interrupt-controller;
                        interrupt-names = "ip2intc_irpt";
                        xlnx,tri-default = <0xffffffff>;
                        xlnx,name = "gpio_shield";
                        xlnx,all-inputs = <0x0>;
                };

                hier_0_PWM_0: PWM@40010000 {
                        phandle = <0x8>;
                        compatible = "xlnx,PWM-1.0";
                        xlnx,ii = <0x1>;
                        xlnx,machine = <0x40>;
                        xlnx,s-axi-control-addr-width = <0x5>;
                        xlnx,ip-name = "PWM";
                        reg = <0x40010000 0x10000>;
                        clocks = <&clkc 0xf>;
                        xlnx,clk-period = <0xa>;
                        xlnx,s-axi-control-data-width = <0x20>;
                        xlnx,edk-iptype = "PERIPHERAL";
                        status = "okay";
                        clock-names = "ap_clk";
                        xlnx,combinational = <0x0>;
                        xlnx,latency = <0x0>;
                        xlnx,name = "hier_0_PWM_0";
                };

                hier_0_gpio_btn_led: gpio@41210000 {
                        phandle = <0xb>;
                        #interrupt-cells = <0x2>;
                        interrupts = <0x0 0x1d 0x4>;
                        xlnx,gpio-board-interface = "btns_2bits";
                        compatible = "xlnx,axi-gpio-2.0", "xlnx,xps-gpio-1.00.a";
                        xlnx,all-outputs = <0x0>;
                        #gpio-cells = <0x2>;
                        xlnx,gpio-width = <0x2>;
                        interrupt-parent = <&intc>;
                        xlnx,dout-default = <0x0>;
                        xlnx,is-dual = <0x1>;
                        xlnx,ip-name = "axi_gpio";
                        xlnx,tri-default-2 = <0xffffffff>;
                        reg = <0x41210000 0x10000>;
                        xlnx,all-inputs-2 = <0x0>;
                        clocks = <&clkc 0xf>;
                        xlnx,all-outputs-2 = <0x1>;
                        gpio-controller;
                        device_type = "gpio";
                        xlnx,interrupt-present = <0x1>;
                        xlnx,gpio2-board-interface = "Custom";
                        xlnx,edk-iptype = "PERIPHERAL";
                        xlnx,dout-default-2 = <0x0>;
                        status = "okay";
                        xlnx,gpio2-width = <0x6>;
                        clock-names = "s_axi_aclk";
                        xlnx,use-board-flow;
                        interrupt-controller;
                        interrupt-names = "ip2intc_irpt";
                        xlnx,tri-default = <0xffffffff>;
                        xlnx,name = "hier_0_gpio_btn_led";
                        xlnx,all-inputs = <0x1>;
                };

                axis_interconnect_0_m00_couplers_auto_ss_slidr: axis_subsetaxis_interconnect_0_m00_couplers_auto_ss_slidr@0 {
                        phandle = <0x58>;
                        compatible = "xlnx,axis-subsetconv-1.1";

                        axis_subset_portsaxis_interconnect_0_m00_couplers_auto_ss_slidr: ports {
                                phandle = <0x59>;
                                #address-cells = <0x1>;
                                #size-cells = <0x0>;

                                axis_subset_port1axis_interconnect_0_m00_couplers_auto_ss_slidr: port@1 {
                                        phandle = <0x5a>;
                                        reg = <0x1>;
                                        xlnx,video-format = <0xc>;

                                        axis_interconnect_0_m00_couplers_auto_ss_slidraxi_dma_0: endpoint {
                                                phandle = <0x5b>;
                                                remote-endpoint = <&axi_dma_0axis_interconnect_0_m00_couplers_auto_ss_slidr>;
                                        };
                                };

                                axis_subset_port0axis_interconnect_0_xbar: port@0 {
                                        phandle = <0x5c>;
                                        reg = <0x0>;
                                        xlnx,video-format = <0xc>;

                                        axi_dma_0axis_interconnect_0_m00_couplers_auto_ss_slidr: endpoint {
                                                phandle = <0x38>;
                                        };
                                };
                        };
                };
        };

        bram_axi_bram_ctrl_0_memory: memory@42000000 {
                phandle = <0x2>;
                ranges = <0x0 0x42000000 0x2000>;
                compatible = "xlnx,axi-bram-ctrl-4.1";
                #address-cells = <0x1>;
                xlnx,ip-name = "axi_bram_ctrl";
                device_type = "memory";
                #size-cells = <0x1>;
                memory_type = "memory";
                reg = <0x42000000 0x2000>;
        };

        ps7_ddr_0_memory: memory@00100000 {
                phandle = <0x4>;
                compatible = "xlnx,ps7-ddr-1.00.a";
                xlnx,ip-name = "ps7_ddr";
                device_type = "memory";
                memory_type = "memory";
                reg = <0x100000 0x1ff00000>;
        };

        ps7_ram_0_memory: memory@0 {
                phandle = <0x5>;
                compatible = "xlnx,ps7-ram-1.00.a";
                xlnx,ip-name = "ps7_ram";
                device_type = "memory";
                memory_type = "memory";
                reg = <0x0 0x30000>;
        };

        ps7_ram_1_memory: memory@ffff0000 {
                phandle = <0x6>;
                compatible = "xlnx,ps7-ram-1.00.a";
                xlnx,ip-name = "ps7_ram";
                device_type = "memory";
                memory_type = "memory";
                reg = <0xffff0000 0xfe00>;
        };

        chosen {
                stdout-path = "serial0:115200n8";
        };

        aliases {
                spi0 = "/amba_pl/axi_quad_spi@41e00000";
                serial0 = "/axi/serial@e0000000";
                serial1 = "/axi/coresight@f8800000";
                spi1 = "/amba_pl/axi_quad_spi@41e10000";
                ethernet0 = "/axi/ethernet@e000b000";
        };

        __symbols__ {
                cpus_a9 = "/cpus-a9@0";
                ps7_cortexa9_0 = "/cpus-a9@0/cpu@0";
                ps7_cortexa9_1 = "/cpus-a9@0/cpu@1";
                fpga_full = "/fpga-region";
                regulator_vccpint = "/fixedregulator";
                replicator_out_port0 = "/replicator/out-ports/port@0/endpoint";
                replicator_out_port1 = "/replicator/out-ports/port@1/endpoint";
                replicator_in_port0 = "/replicator/in-ports/port/endpoint";
                amba = "/axi";
                adc = "/axi/adc@f8007100";
                gpio0 = "/axi/gpio@e000a000";
                intc = "/axi/interrupt-controller@f8f01000";
                L2 = "/axi/cache-controller@f8f02000";
                mc = "/axi/memory-controller@f8006000";
                ocm = "/axi/sram@fffc0000";
                uart0 = "/axi/serial@e0000000";
                gem0 = "/axi/ethernet@e000b000";
                sdhci0 = "/axi/mmc@e0100000";
                slcr = "/axi/slcr@f8000000";
                clkc = "/axi/slcr@f8000000/clkc@100";
                rstc = "/axi/slcr@f8000000/rstc@200";
                pinctrl0 = "/axi/slcr@f8000000/pinctrl@700";
                dmac_s = "/axi/dma-controller@f8003000";
                devcfg = "/axi/devcfg@f8007000";
                efuse = "/axi/efuse@f800d000";
                global_timer = "/axi/timer@f8f00200";
                ttc0 = "/axi/timer@f8001000";
                ttc1 = "/axi/timer@f8002000";
                scutimer = "/axi/timer@f8f00600";
                scuwdt = "/axi/scuwatchdog@f8f00620";
                usb0 = "/axi/usb@e0002000";
                watchdog0 = "/axi/watchdog@f8005000";
                coresight = "/axi/coresight@f8800000";
                etb_in_port = "/axi/etb@f8801000/in-ports/port/endpoint";
                tpiu_in_port = "/axi/tpiu@f8803000/in-ports/port/endpoint";
                funnel_out_port = "/axi/funnel@f8804000/out-ports/port/endpoint";
                funnel0_in_port0 = "/axi/funnel@f8804000/in-ports/port@0/endpoint";
                funnel0_in_port1 = "/axi/funnel@f8804000/in-ports/port@1/endpoint";
                ptm0_out_port = "/axi/ptm@f889c000/out-ports/port/endpoint";
                ptm1_out_port = "/axi/ptm@f889d000/out-ports/port/endpoint";
                ps7_pmu_0 = "/axi/ps7_pmu@f8891000";
                ps7_ocmc_0 = "/axi/ps7_ocmc@f800c000";
                ps7_gpv_0 = "/axi/ps7_gpv@f8900000";
                ps7_scuc_0 = "/axi/ps7_scuc@f8f00000";
                ps7_iop_bus_config_0 = "/axi/ps7_iop_bus_config@e0200000";
                ps7_dma_ns = "/axi/ps7_dma@f8004000";
                ps7_afi_0 = "/axi/ps7_afi@f8008000";
                ps7_afi_1 = "/axi/ps7_afi@f8009000";
                ps7_afi_2 = "/axi/ps7_afi@f800a000";
                ps7_afi_3 = "/axi/ps7_afi@f800b000";
                amba_pl = "/amba_pl";
                clocking0 = "/amba_pl/clocking0";
                adc_adc_adapter_0 = "/amba_pl/adc_adapter@40000000";
                adc_xadc_wiz_0 = "/amba_pl/xadc_wiz@43c00000";
                axi_dma_0 = "/amba_pl/dma@40400000";
                dma_channel_40400000 = "/amba_pl/dma@40400000/dma-channel@40400000";
                dma_channel_40400030 = "/amba_pl/dma@40400000/dma-channel@40400030";
                axi_quad_spi_0 = "/amba_pl/axi_quad_spi@41e00000";
                axi_quad_spi_1 = "/amba_pl/axi_quad_spi@41e10000";
                bram_axi_bram_ctrl_0 = "/amba_pl/bram_axi_bram_ctrl_0@42000000";
                gpio_shield = "/amba_pl/gpio@41200000";
                hier_0_PWM_0 = "/amba_pl/PWM@40010000";
                hier_0_gpio_btn_led = "/amba_pl/gpio@41210000";
                axis_interconnect_0_m00_couplers_auto_ss_slidr = "/amba_pl/axis_subsetaxis_interconnect_0_m00_couplers_auto_ss_slidr@0";
                axis_subset_portsaxis_interconnect_0_m00_couplers_auto_ss_slidr = "/amba_pl/axis_subsetaxis_interconnect_0_m00_couplers_auto_ss_slidr@0/ports";
                axis_subset_port1axis_interconnect_0_m00_couplers_auto_ss_slidr = "/amba_pl/axis_subsetaxis_interconnect_0_m00_couplers_auto_ss_slidr@0/ports/port@1";
                axis_interconnect_0_m00_couplers_auto_ss_slidraxi_dma_0 = "/amba_pl/axis_subsetaxis_interconnect_0_m00_couplers_auto_ss_slidr@0/ports/port@1/endpoint";
                axis_subset_port0axis_interconnect_0_xbar = "/amba_pl/axis_subsetaxis_interconnect_0_m00_couplers_auto_ss_slidr@0/ports/port@0";
                axi_dma_0axis_interconnect_0_m00_couplers_auto_ss_slidr = "/amba_pl/axis_subsetaxis_interconnect_0_m00_couplers_auto_ss_slidr@0/ports/port@0/endpoint";
                bram_axi_bram_ctrl_0_memory = "/memory@42000000";
                ps7_ddr_0_memory = "/memory@00100000";
                ps7_ram_0_memory = "/memory@0";
                ps7_ram_1_memory = "/memory@ffff0000";
        };
};
